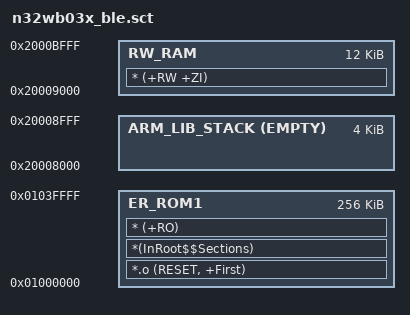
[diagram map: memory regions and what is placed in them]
; *************************************************************
; *** Scatter-Loading Description File generated by uVision ***
; **************for NS32WB03X(256K+48K)************************
; *************************************************************
;BOOT_ROM 0x00000000 0x8000
;{
;    BOOT_ROM1 0x00000000 0x8000
;	{
;	    Startup_boot.o (RESET_BOOT, +First)
;	}
;}

LR_ROM1 0x01000000 0x40000 	  		
{
	ER_ROM1 0x01000000 0x40000  	    
	{
   		*.o (RESET, +First)
   		*(InRoot$$Sections)
  		* (+RO)
  	}
    
    ;ARM_LIB_STACK 0x20001000 EMPTY -0x1000 
  	;{
    
  	;}
    
    ;RW_RAM 0x20008000 0x4000         ;6K RW ZI           
	;{
  		;* (+RW +ZI)
  	;}
    
    ARM_LIB_STACK 0x20009000 EMPTY -0x1000 
  	{
    
  	}
    
    RW_RAM 0x20009000 0x3000         ;6K RW ZI           
	{
  		* (+RW +ZI)
  	}
    
}


;PATCH_RAMCODE 
